# STM32L062 register map
File version: 1.2
CPU: CM0+ r0p0, little endian, MPU, no FPU, 4 interrupt priority bits
Registers are 32-bit, read-write, reset 0x0 unless marked. A register's access mark holds for its fields unless they carry their own. Offsets are from the block's base; lines under a group give offsets from that group; [hi:lo] are bit positions; {n}, {i} and the like mark numbered series; 'fields as' and 'values as' point back to an identical list; <NAME> marks a mode.

## Memory map
0x40000000 TIM2 size 0x400 — General-purpose-timers
0x40000400 TIM3 size 0x400
0x40001000 TIM6 size 0x400 — Basic-timers
0x40001400 TIM7 size 0x400
0x40002800 RTC size 0x400 — Real-time clock
0x40002C00 WWDG size 0x400 — System window watchdog
0x40003000 IWDG size 0x400 — Independent watchdog
0x40003800 SPI2 size 0x400
0x40004400 USART2 size 0x400
0x40004800 LPUSART1 size 0x400 — Universal synchronous asynchronous receiver transmitter
0x40004C00 USART4 size 0x400
0x40005000 USART5 size 0x400
0x40005400 I2C1 size 0x400 — Inter-integrated circuit
0x40005800 I2C2 size 0x400
0x40005C00 USB_FS size 0x400 — Universal serial bus full-speed device interface
0x40006000 USB_SRAM size 0x800 — Universal serial bus full-speed device interface
0x40006C00 CRS size 0x400 — Clock recovery system
0x40007000 PWR size 0x400 — Power control
0x40007400 DAC size 0x400 — Digital-to-analog converter
0x40007800 I2C3 size 0x400
0x40007C00 LPTIM size 0x400 — Low power timer
0x40010000 SYSCFG_COMP size 0x400 — System configuration controller and Comparator
0x40010400 EXTI size 0x400 — External interrupt/event controller
0x40010800 TIM21 size 0x400 — General-purpose-timers
0x40011400 TIM22 size 0x400 — General-purpose-timers
0x40011C00 Firewall size 0x400
0x40012400 ADC size 0x400 — Analog-to-digital converter
0x40013000 SPI1 size 0x400 — Serial peripheral interface
0x40013800 USART1 size 0x400 — Universal synchronous asynchronous receiver transmitter
0x40015800 DBGMCU size 0x400 — Debug support
0x40020000 DMA1 size 0x400 — Direct memory access controller
0x40021000 RCC size 0x400 — Reset and clock control
0x40022000 Flash size 0x400
0x40023000 CRC size 0x400 — Cyclic redundancy check calculation unit
0x40024000 TSC size 0x400 — Touch sensing controller
0x40025000 RNG size 0x400 — Random number generator
0x40026000 AES size 0x400 — Advanced encryption standard hardware accelerator
0x50000000 GPIOA size 0x400 — General-purpose I/Os
0x50000400 GPIOB size 0x400 — General-purpose I/Os
0x50000800 GPIOC size 0x400
0x50000C00 GPIOD size 0x400
0x50001000 GPIOE size 0x400
0x50001C00 GPIOH size 0x400

## Interrupts
0 WWDG — Window Watchdog interrupt
1 PVD (EXTI) — PVD through EXTI line detection
2 RTC — RTC global interrupt
4 RCC — RCC global interrupt
5 EXTI0_1 (EXTI) — EXTI Line[1:0] interrupts
6 EXTI2_3 (EXTI) — EXTI Line[3:2] interrupts
7 EXTI4_15 (EXTI) — EXTI Line15 and EXTI4 interrupts
8 TSC — Touch sensing interrupt
9 DMA1_Channel1 (DMA1) — DMA1 Channel1 global interrupt
10 DMA1_Channel2_3 (DMA1) — DMA1 Channel2 and 3 interrupts
11 DMA1_Channel4_7 (DMA1) — DMA1 Channel4 to 7 interrupts
12 ADC_COMP (ADC) — ADC and comparator 1 and 2
13 LPTIM1 (LPTIM) — LPTIMER1 interrupt through EXTI29
14 USART4_USART5 (USART4) — USART4/USART5 global interrupt
15 TIM2 — TIM2 global interrupt
16 TIM3 — TIM3 global interrupt
17 TIM6_DAC (TIM6) — TIM6 global interrupt and DAC
18 TIM7 — TIM7 global interrupt and DAC
20 TIM21 — TIMER21 global interrupt
21 I2C3 (PWR) — I2C3 global interrupt
22 TIM22 — TIMER22 global interrupt
23 I2C1 — I2C1 global interrupt
24 I2C2 — I2C2 global interrupt
25 SPI1 — SPI1_global_interrupt
26 SPI2 — SPI2 global interrupt
27 USART1 — USART1 global interrupt
28 USART2 — USART2 global interrupt
29 AES_RNG_LPUART1 (AES) — AES global interrupt RNG global interrupt and LPUART1 global interrupt through
31 USB (USB_FS) — USB event interrupt through EXTI18

## AES — Advanced encryption standard hardware accelerator
Base 0x40026000
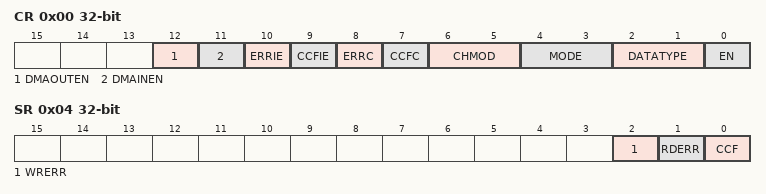
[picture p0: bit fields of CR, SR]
0x00 CR — control register
  [12] DMAOUTEN — Enable DMA management of data output phase
  [11] DMAINEN — Enable DMA management of data input phase
  [10] ERRIE — Error interrupt enable
  [9] CCFIE — CCF flag interrupt enable
  [8] ERRC — Error clear
  [7] CCFC — Computation Complete Flag Clear
  [6:5] CHMOD — AES chaining mode
  [4:3] MODE — AES operating mode
  [2:1] DATATYPE — Data type selection (for data in and data out to/from the cryptographic block)
  [0] EN — AES enable
0x04 SR ro — status register
  [2] WRERR — Write error flag
  [1] RDERR — Read error flag
  [0] CCF — Computation complete flag
0x08 DINR — data input register
  [31:0] AES_DINR — Data Input Register.
0x0C DOUTR ro — data output register
  [31:0] AES_DOUTR — Data output register
0x10 KEYR0 — key register 0
  [31:0] AES_KEYR0 — Data Output Register (LSB key [31:0])
0x14 KEYR1 — key register 1
  [31:0] AES_KEYR1 — AES key register (key [63:32])
0x18 KEYR2 — key register 2
  [31:0] AES_KEYR2 — AES key register (key [95:64])
0x1C KEYR3 — key register 3
  [31:0] AES_KEYR3 — AES key register (MSB key [127:96])
0x20 IVR0 — initialization vector register 0
  [31:0] AES_IVR0 — initialization vector register (LSB IVR [31:0])
0x24 IVR1 — initialization vector register 1
  [31:0] AES_IVR1 — Initialization Vector Register (IVR [63:32])
0x28 IVR2 — initialization vector register 2
  [31:0] AES_IVR2 — Initialization Vector Register (IVR [95:64])
0x2C IVR3 — initialization vector register 3
  [31:0] AES_IVR3 — Initialization Vector Register (MSB IVR [127:96])

## Notices in the file
Copyright (c) 2024 STMicroelectronics.
SPDX-License-Identifier: Apache-2.0
Licensed under the Apache License, Version 2.0 (the "License");
you may not use this file except in compliance with the License.
You may obtain a copy of the License at
http://www.apache.org/licenses/LICENSE-2.0
Unless required by applicable law or agreed to in writing, software
distributed under the License is distributed on an "AS IS" BASIS,
WITHOUT WARRANTIES OR CONDITIONS OF ANY KIND, either express or implied.
See the License for the specific language governing permissions and
limitations under the License.
